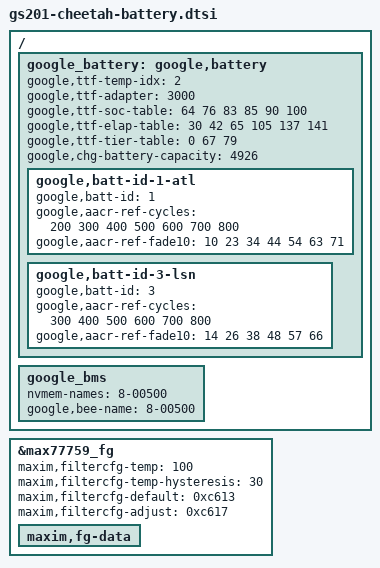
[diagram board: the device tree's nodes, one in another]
// SPDX-License-Identifier: GPL-2.0-only
/*
 * Battery device tree entries specific to raven
 *
 * Copyright 2021 Google,LLC
 *
 */

&google_battery {
	google,chg-battery-capacity = <4926>;
};

&max77759_fg {
	/delete-property/ maxim,force-batt-id;

	maxim,filtercfg-temp = <100>;
	maxim,filtercfg-temp-hysteresis = <30>;
	maxim,filtercfg-default = /bits/ 16 <0xc613>;
	maxim,filtercfg-adjust = /bits/ 16 <0xc617>;

	maxim,fg-data {
		#include "gs201-cheetah-battery-data.dtsi"
	};
};

/ {
	fragment@battery {
		target-path = "/";
		__overlay__ {
			google_battery: google,battery {
				google,ttf-temp-idx= <2>;
				google,ttf-adapter = <3000>;
				google,ttf-soc-table =  <64 76 83 85  90  100>;
				google,ttf-elap-table = <30 42 65 105 137 141>;
				google,ttf-tier-table = <0 67 79>;

				google,batt-id-1-atl {
					google,batt-id = <1>;
					google,aacr-ref-cycles = <200 300 400 500 600 700 800>;
					google,aacr-ref-fade10 = < 10  23  34  44  54  63  71>;
				};

				google,batt-id-3-lsn {
					google,batt-id = <3>;
					google,aacr-ref-cycles = <300 400 500 600 700 800>;
					google,aacr-ref-fade10 = < 14  26  38  48  57  66>;
				};
			};

			google_bms {
				nvmem-names = "8-00500";
				/* pack eeprom is available only with P20+ batteries */
				google,bee-name = "8-00500";
			};
		};
	};
};
